# SN32F400 register map
Vendor: SONiX Technology Co., Ltd.; Series: SN32F400; File version: 1.1
CPU: CM0 r0p0, little endian, no MPU, no FPU, 2 interrupt priority bits
Registers are 32-bit, read-write, reset 0x0 unless marked. A register's access mark holds for its fields unless they carry their own. Offsets are from the block's base; [hi:lo] are bit positions; {n}, {i} and the like mark numbered series; 'fields as' and 'values as' point back to an identical list.

## SN_CT16B0 — 16-bit Timer 0 with Capture function
Base 0x40000000
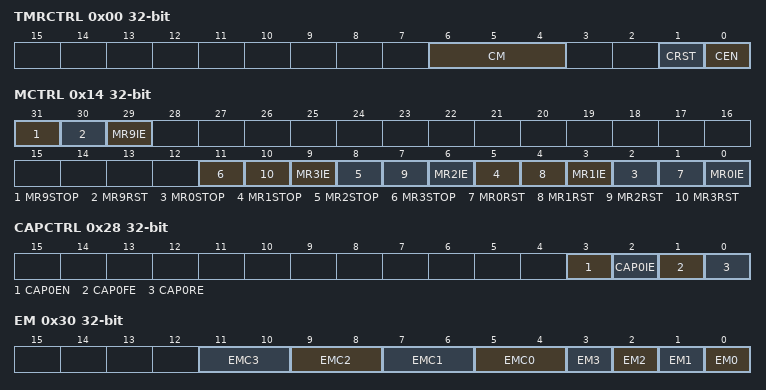
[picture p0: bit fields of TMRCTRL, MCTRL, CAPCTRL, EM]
0x00 TMRCTRL — Offset:0x00 CT16Bn Timer Control register
  [6:4] CM — Counting mode selection
    0=Up-counting mode (Edge-aligned Up-counting mode); 1=Down-counting mode (Edge-aligned Down-counting mode); 2=Center-aligned counting mode 1 (The match interrupt flag is set during the down-counting period); 4=Center-aligned counting mode 2 (The match interrupt flag is set during the up-counting period); 6=Center-aligned counting mode 3 (The match interrupt flag is set during both up-counting and down-counting period)
  [1] CRST — Counter Reset
    0=Disable counter reset; 1=Reset Counter (Timer Counter and the Prescale Counter are synchronously reset on the next positive edge of PCLK)
  [0] CEN — Counter enable
    0=Disable counter; 1=Enable Timer Counter and Prescale Counter for counting
0x04 TC — Offset:0x04 CT16Bn Timer Counter register
  [15:0] TC — Timer Counter
0x08 PRE — Offset:0x08 CT16Bn Prescale register
  [7:0] PRE — Prescaler
0x0C PC — Offset:0x0C CT16Bn Prescale Counter register
  [7:0] PC — Prescaler Counter
0x10 CNTCTRL — Offset:0x10 CT16Bn Counter Control register
  [1:0] CTM — Counter/Timer Mode
    0=Timer Mode: every rising PCLK edge; 1=Counter Mode 1 (TC is incremented on rising edges on the CAP0 input); 2=Counter Mode 2 (TC is incremented on falling edges on the CAP0 input); 3=Counter Mode 3 (TC is incremented on both edges on the CAP0 input)
0x14 MCTRL — Offset:0x14 CT16Bn Match Control register
  [31] MR9STOP — Stop TC and PC and clear CEN bit when MR9 matches TC
    0=Disable stop TC and PC; 1=Enable (Stop TC and PC and clear CEN bit when MR9 matches TC)
  [30] MR9RST — Enable reset TC when MR9 matches TC
    0=Disable reset TC; 1=Enable (Reset TC when MR9 matches TC)
  [29] MR9IE — Enable generating an interrupt based on CM[2:0] when MR9 matches the value in the TC
    0=Disable generating an interrupt; 1=Enable (Generating an interrupt when MR9 matches TC)
  [3n+2] MR{n}STOP (n=0..3) — Stop TC and PC and clear CEN bit when MR{n} matches TC
    0=Disable stop TC and PC; 1=Enable (Stop TC and PC and clear CEN bit when MR{n} matches TC)
  [3n+1] MR{n}RST (n=0..3) — Enable reset TC when MR{n} matches TC
    0=Disable reset TC; 1=Enable (Reset TC when MR{n} matches TC)
  [3n] MR{n}IE (n=0..3) — Enable generating an interrupt when MR{n} matches TC
    0=Disable generating an interrupt; 1=Enable (Generating an interrupt when MR{n} matches TC)
{0x18+4i} MR{i} (i=0..3) — Offset:{0x18+4i} CT16Bn MR{i} register
  [15:0] MR — Timer counter match value
0x28 CAPCTRL — Offset:0x28 CT16Bn Capture Control register
  [3] CAP0EN — CAP0 function enable
    0=Disable capture function; 1=Enable CAP0 function for external Capture pin
  [2] CAP0IE — Interrupt on CT16Bn_CAP0 event
    0=Disable interrupt; 1=Enable (A CAP0 load due to a CT16Bn_CAP0 event will generate an interrupt.)
  [1] CAP0FE — Capture/Reset on CT16Bn_CAP0 signal falling edge
    0=Disable (No action); 1=Enable (A sequence of 1 then 0 on CT16Bn_CAP0 will cause CAP0 to be loaded with the contents of TC.)
  [0] CAP0RE — Capture/Reset on CT16Bn_CAP0 signal rising edge
    0=Disable (No action); 1=Enable (A sequence of 0 then 1 on CT16Bn_CAP0 will cause CAP0 to be loaded with the contents of TC)
0x2C CAP0 ro — Offset:0x2C CT16Bn CAP0 register
  [15:0] CAP0 — Timer counter capture value
0x30 EM — Offset:0x30 CT16Bn External Match register
  [2n+5:2n+4] EMC{n} (n=0..3) — CT16Bn_PWM{n} functionality when MR{n}=TC
    0=Nothing (Do nothing); 1=Low (CT16Bn_PWM{n} pin is LOW); 2=High (CT16Bn_PWM{n} pin is HIGH); 3=Toggle CT16Bn_PWM{n} pin
  [n] EM{n} (n=0..3) — When the TC doesn't match MR{n} and EMC{n} is not 0, this bit will drive the state of CT16Bn_PWM{n} output
    0=Low (Drive the state of CT16Bn_PWM{n} output to Low when the TC doesn't match MR{n} and EMC{n} is not 0); 1=High (Drive the state of CT16Bn_PWM{n} output to High when the TC doesn't match MR{n} and EMC{n} is not 0)
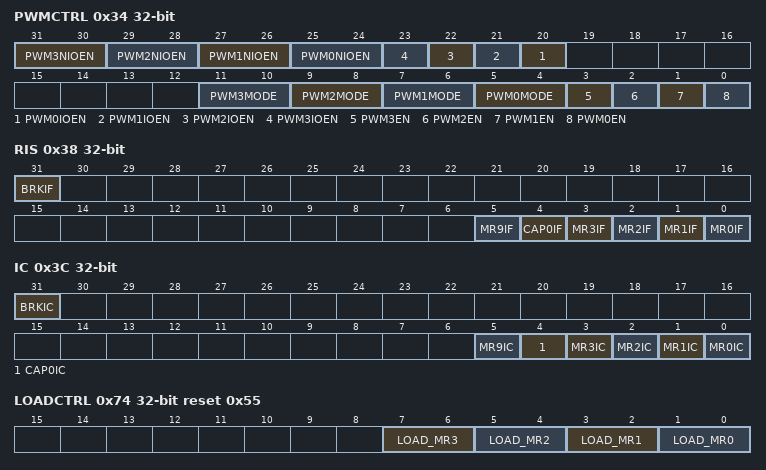
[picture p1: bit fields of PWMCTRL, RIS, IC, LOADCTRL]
0x34 PWMCTRL — Offset:0x34 CT16Bn PWM Control register
  [31:30] PWM3NIOEN — CT16Bn_PWM3N/GPIO selection bit
    0=GPIO (CT16Bn_PWM3N pin is act as GPIO); 1=Inverse1 (CT16Bn_PWM3N pin outputs the inverse signal with dead-band of CT16Bn_PWM3, but same High signal during dead-band period); 2=Inverse2 (CT16Bn_PWM3N pin outputs the inverse signal with dead-band of CT16Bn_PWM3, but same Low signal during dead-band period); 3=Same (CT16Bn_PWM3N pin outputs the same signal with dead-band of CT16Bn_PWM3)
  [29:28] PWM2NIOEN — CT16Bn_PWM0N/GPIO selection bit
    0=GPIO (CT16Bn_PWM2N pin is act as GPIO); 1=Inverse1 (CT16Bn_PWM2N pin outputs the inverse signal with dead-band of CT16Bn_PWM0, but same High signal during dead-band period); 2=Inverse2 (CT16Bn_PWM2N pin outputs the inverse signal with dead-band of CT16Bn_PWM0, but same Low signal during dead-band period); 3=Same (CT16Bn_PWM2N pin outputs the same signal with dead-band of CT16Bn_PWM0)
  [27:26] PWM1NIOEN — CT16Bn_PWM0N/GPIO selection bit
    0=GPIO (CT16Bn_PWM1N pin is act as GPIO); 1=Inverse1 (CT16Bn_PWM1N pin outputs the inverse signal with dead-band of CT16Bn_PWM0, but same High signal during dead-band period); 2=Inverse2 (CT16Bn_PWM1N pin outputs the inverse signal with dead-band of CT16Bn_PWM0, but same Low signal during dead-band period); 3=Same (CT16Bn_PWM1N pin outputs the same signal with dead-band of CT16Bn_PWM0)
  [25:24] PWM0NIOEN — CT16Bn_PWM0N/GPIO selection bit
    0=GPIO (CT16Bn_PWM0N pin is act as GPIO); 1=Inverse1 (CT16Bn_PWM0N pin outputs the inverse signal with dead-band of CT16Bn_PWM0, but same High signal during dead-band period); 2=Inverse2 (CT16Bn_PWM0N pin outputs the inverse signal with dead-band of CT16Bn_PWM0, but same Low signal during dead-band period); 3=Same (CT16Bn_PWM0N pin outputs the same signal with dead-band of CT16Bn_PWM0)
  [n+20] PWM{n}IOEN (n=0..3) — CT16Bn_PWM{n}/GPIO selection
    0=Disable (CT16Bn_PWM{n} pin is act as GPIO); 1=Enable (CT16Bn_PWM{n} pin act as match output, and output depends on PWM{n}EN bit)
  [2n+5:2n+4] PWM{n}MODE (n=0..3) — PWM{n} output mode
    0=PWM mode 1 (During up-counting, PWM{n} is 0 when TC is less than MR{n}.); 1=PWM mode 2 (During up-counting, PWM{n} is 1 when TC is less than MR{n}.); 2=Force 0 (PWM{n} is forced to 0); 3=Force 1 (PWM{n} is forced to 1)
  [3] PWM3EN — PWM2 enable
    0=Disable (CT16Bn_PWM3 is controlled by EMC3); 1=Enable PWM mode for CT16Bn_PWM3
  [2] PWM2EN — PWM2 enable
    0=Disable (CT16Bn_PWM2 is controlled by EMC2); 1=Enable PWM mode for CT16Bn_PWM2
  [1] PWM1EN — PWM1 enable
    0=Disable (CT16Bn_PWM1 is controlled by EMC1); 1=Enable PWM mode for CT16Bn_PWM1
  [0] PWM0EN — PWM0 enable
    0=Disable (CT16Bn_PWM0 is controlled by EMC0); 1=Enable PWM mode for CT16Bn_PWM0
0x38 RIS ro — Offset:0x38 CT16Bn Raw Interrupt Status register
  [31] BRKIF — Break interrupt flag
    0=No (No break condition occurs); 1=Met interrupt requirements (Break condition occurs)
  [5] MR9IF — Match channel 9 interrupt flag
    0=No (No interrupt on match channel 9); 1=Met interrupt requirements (Interrupt requirements met on match channel 9)
  [4] CAP0IF — Capture channel 0 interrupt flag
    0=No (No interrupt on CAP0); 1=Met interrupt requirements (Interrupt requirements met on CAP0)
  [n] MR{n}IF (n=0..3) — Match channel {n} interrupt flag
    0=No (No interrupt on match channel {n}); 1=Met interrupt requirements (Interrupt requirements met on match channel {n})
0x3C IC wo — Offset:0x3C CT16Bn Interrupt Clear register
  [31] BRKIC — BRKIF clear bit
    0=None (No effect); 1=Clear BRKIF
  [5] MR9IC — MR9IF clear bit
    0=None (No effect); 1=Clear MR9IF
  [4] CAP0IC — CAP0IF clear bit
    0=None (No effect); 1=Clear CAP0IF
  [n] MR{n}IC (n=0..3) — MR{n}IF clear bit
    0=None (No effect); 1=Clear MR{n}IF
0x40 MR9 — Offset:0x40 CT16Bn MR9 register
  [15:0] MR — Timer counter match value
{0x44+4i} PWM{i}NDB (i=0..3) — Offset:{0x44+4i} CT16Bn PWM{i}N Dead-band Period register
  [9:0] DB — PWM{i}N output dead-band period time=DB*CT16Bn_PCLK*(PR+1) cycle
0x74 LOADCTRL reset 0x55 — Offset:0x74 CT16Bn PWM Load Mode Control register
  [7:6] LOAD_MR3 — MR3 load mode selection in center-aligned mode
    0=00b (No effect); 1=01b (Load MR3 value at TC=0 and MR3 value is unchanged at TC=MR9); 2=10b (MR3 value is unchanged at TC=0 and Load MR3 value at TC=MR9); 3=11b (Load MR3 value at TC=0 and TC=MR9)
  [5:4] LOAD_MR2 — MR2 load mode selection in center-aligned mode
    0=00b (No effect); 1=01b (Load MR2 value at TC=0 and MR2 value is unchanged at TC=MR9); 2=10b (MR2 value is unchanged at TC=0 and Load MR0 value at TC=MR9); 3=11b (Load MR2 value at TC=0 and TC=MR9)
  [3:2] LOAD_MR1 — MR1 load mode selection in center-aligned mode
    0=00b (No effect); 1=01b (Load MR1 value at TC=0 and MR1 value is unchanged at TC=MR9); 2=10b (MR1 value is unchanged at TC=0 and Load MR1 value at TC=MR9); 3=11b (Load MR1 value at TC=0 and TC=MR9)
  [1:0] LOAD_MR0 — MR0 load mode selection in center-aligned mode
    0=00b (No effect); 1=01b (Load MR0 value at TC=0 and MR0 value is unchanged at TC=MR9); 2=10b (MR0 value is unchanged at TC=0 and Load MR0 value at TC=MR9); 3=11b (Load MR0 value at TC=0 and TC=MR9)
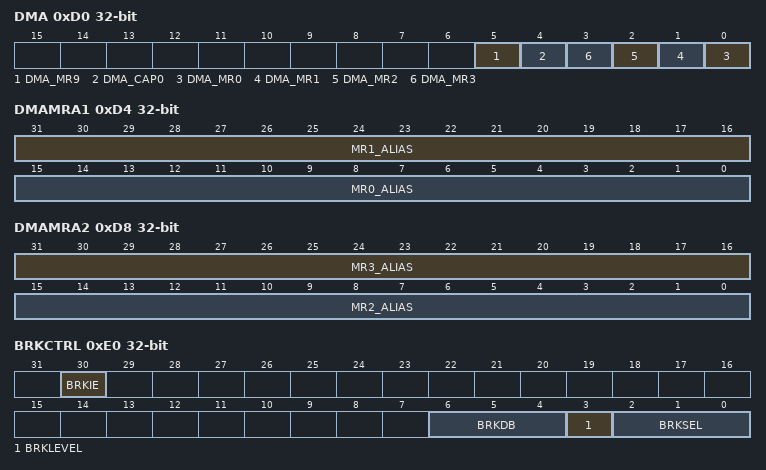
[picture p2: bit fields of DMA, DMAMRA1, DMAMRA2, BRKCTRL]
0xD0 DMA — Offset:0xD0 CT16Bn DMA mode register
  [5] DMA_MR9 — MR9 DMA request active enable
    0=Disable. MR9 DMA request cannot issue.; 1=Enable. MR9 DMA request can issue.
  [4] DMA_CAP0 — CAP0 DMA request active enable
    0=Disable. CAP0 DMA request cannot issue.; 1=Enable. CAP0 DMA request can issue.
  [n] DMA_MR{n} (n=0..3) — MR{n} DMA request active enable
    0=Disable. MR{n} DMA request cannot issue.; 1=Enable. MR{n} DMA request can issue.
0xD4 DMAMRA1 wo — Offset:0xD4 CT16Bn DMA MR Alias register 1
  [31:16] MR1_ALIAS — MR1 alias for DMA access
  [15:0] MR0_ALIAS — MR0 alias for DMA access
0xD8 DMAMRA2 wo — Offset:0xD8 CT16Bn DMA MR Alias register 2
  [31:16] MR3_ALIAS — MR3 alias for DMA access
  [15:0] MR2_ALIAS — MR2 alias for DMA access
0xE0 BRKCTRL — Offset:0xE0 CT16Bn Break Function Control register
  [30] BRKIE — Enable generating an interrupt when BRKIF = 1
    0=Disable generating an interrup; 1=Enable (Generating an interrupt when BRKIF = 1)
  [6:4] BRKDB — Break pin (BRK) debounce time
    0=1T (Debounce time=1*CT16B0_PCLK); 1=2T (Debounce time=2*CT16B0_PCLK); 2=4T (Debounce time=4*CT16B0_PCLK); 3=8T (Debounce time=8*CT16B0_PCLK); 4=16T (Debounce time=16*CT16B0_PCLK); 5=32T (Debounce time=32*CT16B0_PCLK); 6=64T (Debounce time=64*CT16B0_PCLK); 7=128T (Debounce time=128*CT16B0_PCLK)
  [3] BRKLEVEL — The trigger level of PWM channels break function
    0=0b (Low level. (CMP V- > V+)); 1=1b (High level. (CMP V+ > V-))
  [2:0] BRKSEL — The trigger source selection of PWM channels break function
    0=000b (Disable); 1=001b (CMP0 output); 2=010b (CMP1 output); 3=011b (CMP2 output); 4=100b (Break pin (BRK)); 5=101b (Noise detect output)

## SN_CT16B1 — 16-bit Timer 1 with Capture function
Base 0x40002000
Registers as SN_CT16B0, without PWM{n}NDB (n=0..3), BRKCTRL; these are added or differ:
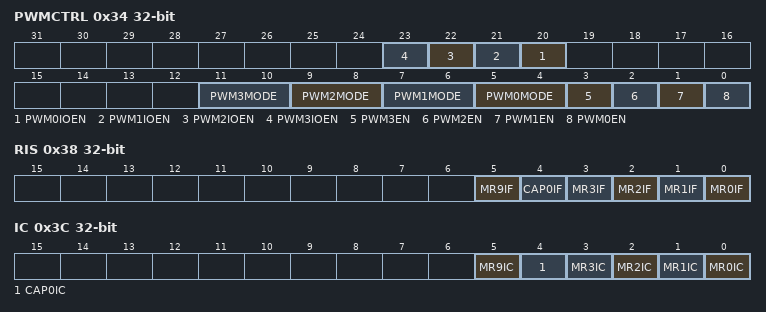
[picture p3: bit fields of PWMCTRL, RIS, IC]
0x34 PWMCTRL — Offset:0x34 CT16Bn PWM Control register
  [n+20] PWM{n}IOEN (n=0..3) — CT16Bn_PWM{n}/GPIO selection
    0=Disable (CT16Bn_PWM{n} pin is act as GPIO); 1=Enable (CT16Bn_PWM{n} pin act as match output, and output depends on PWM{n}EN bit)
  [2n+5:2n+4] PWM{n}MODE (n=0..3) — PWM{n} output mode
    values as SN_CT16B0.PWMCTRL.PWM0MODE
  [3] PWM3EN — PWM2 enable
    0=Disable (CT16Bn_PWM3 is controlled by EMC3); 1=Enable PWM mode for CT16Bn_PWM3
  [2] PWM2EN — PWM2 enable
    0=Disable (CT16Bn_PWM2 is controlled by EMC2); 1=Enable PWM mode for CT16Bn_PWM2
  [1] PWM1EN — PWM1 enable
    0=Disable (CT16Bn_PWM1 is controlled by EMC1); 1=Enable PWM mode for CT16Bn_PWM1
  [0] PWM0EN — PWM0 enable
    0=Disable (CT16Bn_PWM0 is controlled by EMC0); 1=Enable PWM mode for CT16Bn_PWM0
0x38 RIS ro — Offset:0x38 CT16Bn Raw Interrupt Status register
  [5] MR9IF — Match channel 9 interrupt flag
    0=No (No interrupt on match channel 9); 1=Met interrupt requirements (Interrupt requirements met on match channel 9)
  [4] CAP0IF — Capture channel 0 interrupt flag
    0=No (No interrupt on CAP0); 1=Met interrupt requirements (Interrupt requirements met on CAP0)
  [n] MR{n}IF (n=0..3) — Match channel {n} interrupt flag
    0=No (No interrupt on match channel {n}); 1=Met interrupt requirements (Interrupt requirements met on match channel {n})
0x3C IC wo — Offset:0x3C CT16Bn Interrupt Clear register
  [5] MR9IC — MR9IF clear bit
    0=None (No effect); 1=Clear MR9IF
  [4] CAP0IC — CAP0IF clear bit
    0=None (No effect); 1=Clear CAP0IF
  [n] MR{n}IC (n=0..3) — MR{n}IF clear bit
    0=None (No effect); 1=Clear MR{n}IF

## SN_CT16B5 — 16-bit Timer 5 with Capture function
Base 0x4000A000
Registers as SN_CT16B1; these are added or differ:
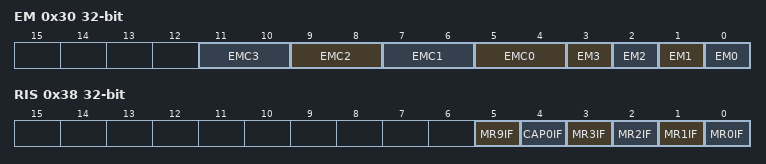
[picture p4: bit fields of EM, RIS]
0x30 EM — Offset:0x30 CT16Bn External Match register
  [2n+5:2n+4] EMC{n} (n=0..3) — CT16Bn_PWM{n} functionality when MR{n}=TC
    0=Nothing (Do nothing); 1=Low (CT16Bn_PWM{n} pin is LOW); 2=High (CT16Bn_PWM{n} pin is HIGH); 3=Toggle CT16Bn_PWM{n} pin
  [3] EM3 — When the TC doesn't match MR3 and EMC3 is not 0, this bit will drive the state of CT16Bn_PWM3 output.
    0=Low (Drive the state of CT16Bn_PWM3 output to Low when the TC doesn't match MR3 and EMC3 is not 0); 1=High (Drive the state of CT16Bn_PWM3 output to High when the TC doesn't match MR3 and EMC3 is not 0)
  [2] EM2 — When the TC doesn't match MR2 and EMC2 is not 0, this bit will drive the state of CT16Bn_PWM2 output
    0=Low (Drive the state of CT16Bn_PWM2 output to Low when the TC doesn't match MR2 and EMC2 is not 0); 1=High (Drive the state of CT16Bn_PWM2 output to High when the TC doesn't match MR2 and EMC2 is not 0)
  [1] EM1 — When the TC doesn't match MR1 and EMC1 is not 0, this bit will drive the state of CT16Bn_PWM1 output
    0=Low (Drive the state of CT16Bn_PWM1 output to Low when the TC doesn't match MR1 and EMC1 is not 0); 1=High (Drive the state of CT16Bn_PWM1 output to High when the TC doesn't match MR1 and EMC1 is not 0)
  [0] EM0 — When the TC doesn't match MR0 and EMC0 is not 0, this bit will drive the state of CT16Bn_PWM0 output
    0=Low (Drive the state of CT16Bn_PWM0 output to Low when the TC doesn't match MR0 and EMC0 is not 0); 1=High (Drive the state of CT16Bn_PWM0 output to High when the TC doesn't match MR0 and EMC0 is not 0)
0x38 RIS ro — Offset:0x38 CT16Bn Raw Interrupt Status register
  [5] MR9IF — Match channel 9 interrupt flag
    0=No (No interrupt on match channel 9); 1=Met interrupt requirements (Interrupt requirements met on match channel 9)
  [4] CAP0IF — Capture channel 0 interrupt flag
    0=No (No interrupt on CAP0); 1=Met interrupt requirements (Interrupt requirements met on CAP0)
  [3] MR3IF — Match channel 3 interrupt flag
    0=No (No interrupt on match channel 3); 1=Met interrupt requirements (Interrupt requirements met on match channel 3)
  [2] MR2IF — Match channel 2 interrupt flag
    0=No (No interrupt on match channel 2); 1=Met interrupt requirements (Interrupt requirements met on match channel 2)
  [1] MR1IF — Match channel 1 interrupt flag
    0=No (No interrupt on match channel 1); 1=Met interrupt requirements (Interrupt requirements met on match channel 1)
  [0] MR0IF — Match channel 0 interrupt flag
    0=No interrupt on match channel 0; 1=Met interrupt requirements (Interrupt requirements met on match channel 0)
